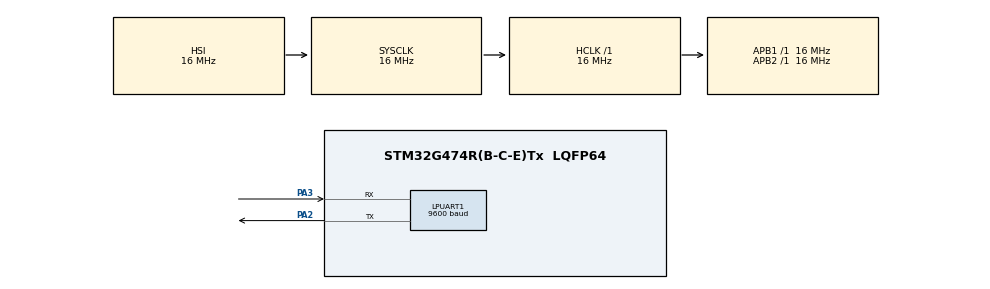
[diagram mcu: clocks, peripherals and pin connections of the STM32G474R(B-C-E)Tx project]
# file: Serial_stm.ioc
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LPUART1.BaudRate=9600
Mcu.Family=STM32G4
Mcu.Name=STM32G474R(B-C-E)Tx
Mcu.Package=LQFP64
NVIC.LPUART1_IRQn=true\:0\:0\:false\:false\:true\:true\:true
NVIC.PriorityGroup=NVIC_PRIORITYGROUP_4
PA2.Mode=Asynchronous
PA2.Signal=LPUART1_TX
PA3.Mode=Asynchronous
PA3.Signal=LPUART1_RX
ProjectManager.HeapSize=0x200
ProjectManager.StackSize=0x400
ProjectManager.TargetToolchain=STM32CubeIDE
RCC.AHBFreq_Value=16000000
RCC.APB1Freq_Value=16000000
RCC.APB1TimFreq_Value=16000000
RCC.APB2Freq_Value=16000000
RCC.APB2TimFreq_Value=16000000
RCC.CortexFreq_Value=16000000
RCC.EXTERNAL_CLOCK_VALUE=12288000
RCC.HCLKFreq_Value=16000000
RCC.HSE_VALUE=8000000
RCC.HSI48_VALUE=48000000
RCC.HSI_VALUE=16000000
RCC.LSE_VALUE=32768
RCC.SYSCLKFreq_VALUE=16000000
RCC.USBFreq_Value=64000000
RCC.VCOOutputFreq_Value=128000000
VP_SYS_VS_DBSignals.Mode=DisableDeadBatterySignals
board=custom

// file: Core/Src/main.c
/* USER CODE BEGIN Header */
/**
  ******************************************************************************
  * @file           : main.c
  * @brief          : Main program body
  ******************************************************************************
  * @attention
  *
  * <h2><center>&copy; Copyright (c) 2022 STMicroelectronics.
  * All rights reserved.</center></h2>
  *
  * This software component is licensed by ST under BSD 3-Clause license,
  * the "License"; You may not use this file except in compliance with the
  * License. You may obtain a copy of the License at:
  *                        opensource.org/licenses/BSD-3-Clause
  *
  ******************************************************************************
  */
/* USER CODE END Header */
#include "main.h"
#include "string.h"
#include <stdio.h>
#include <time.h>

UART_HandleTypeDef hlpuart1;

void SystemClock_Config(void);
static void MX_GPIO_Init(void);
static void MX_LPUART1_UART_Init(void);

/* USER CODE BEGIN 0 */
uint8_t data[17];
uint16_t CalcCRC(uint8_t *data_t, uint16_t length)
{
	unsigned int temp, temp2, flag;
	temp = 0xFFFF;
	for(int i = 0; i < length; i++)
	{
		temp = temp ^ data[i];
		for(int j = 0; j < length; j++)
		{
			flag = temp & 0x0001;
			temp >>= 1;
			if(flag)
				temp ^= 0xA001;
		}
	}
	// reverse byte order.
	temp2 = temp >> 8;
	temp = (temp << 8) | temp2;
	temp &= 0xFFFF;
	return temp;
}

//tao 1 mang random 12 phan tu
void initRandomArray(uint8_t *A, int n, uint8_t k) {
    srand(time(NULL));
    uint8_t randNum = 0;
    for (int i = 0; i < n; i++) {
        randNum = 48 + rand() % k;
        A[i] = randNum;
        printf("%d\n", A[i]);
    }
}
/* USER CODE END 0 */

int main(void)
{
  /* USER CODE BEGI5 1 */
  /* USER CODE END 1 */

  /* MCU Configuration--------------------------------------------------------*/

  /* Reset of all peripherals, Initializes the Flash interface and the Systick. */
  HAL_Init();

  /* USER CODE BEGIN Init */
  uint8_t arrayRandom[12];
  uint8_t k = 78;
  int count = 0;
  initRandomArray(arrayRandom, sizeof(arrayRandom), k);
  // truyen gia tri cho data
  data[0] = 0x42;		// byte 0, 1: header
  data[1] = 0x4C;
  data[2] = 0x0C;		// byte 2, 3: byte CMD
  for(int i = 0; i < sizeof(arrayRandom); i++)
  {
	  data[i + 3] = arrayRandom[i];
  }
  data[15] = CalcCRC(data, 15) >> 8;		// byte 15: CRC
  data[16] = CalcCRC(data, 15);
  /* USER CODE END Init */

  /* Configure the system clock */
  SystemClock_Config();

  /* Initialize all configured peripherals */
  MX_GPIO_Init();
  MX_LPUART1_UART_Init();
  /* USER CODE BEGIN 2 */
//  HAL_UART_Receive_IT(&hlpuart1, rxBuffer, 5);
  //HAL_UART_Transmit(&hlpuart1, rxBuffer, 3, 100);
  /* USER CODE END 2 */

  /* Infinite loop */
  while (1)
  {
	 // initRandomArray(arrayRandom, sizeof(arrayRandom), k);
	  HAL_UART_Transmit_IT(&hlpuart1, data, sizeof(data));
	  count++;
	  if(count > 10)
	  {
		  initRandomArray(arrayRandom, sizeof(arrayRandom), k);
		  data[0] = 0x42;		// byte 0, 1: header
		  data[1] = 0x4C;
		  data[2] = 0x0C;		// byte 2, 3: byte CMD
		  for(int i = 0; i < sizeof(arrayRandom); i++)
		  {
			  data[i + 3] = arrayRandom[i];
		  }
		  data[15] = CalcCRC(data, 15) >> 8;		// byte 15: CRC
		  data[16] = CalcCRC(data, 15);
		  count = 0;
	  }
	  HAL_Delay(1000);
  }
}

void SystemClock_Config(void)
{
  RCC_OscInitTypeDef RCC_OscInitStruct = {0};
  RCC_ClkInitTypeDef RCC_ClkInitStruct = {0};
  RCC_PeriphCLKInitTypeDef PeriphClkInit = {0};

  /** Configure the main internal regulator output voltage
  */
  HAL_PWREx_ControlVoltageScaling(PWR_REGULATOR_VOLTAGE_SCALE1);
  /** Initializes the RCC Oscillators according to the specified parameters
  * in the RCC_OscInitTypeDef structure.
  */
  RCC_OscInitStruct.OscillatorType = RCC_OSCILLATORTYPE_HSI;
  RCC_OscInitStruct.HSIState = RCC_HSI_ON;
  RCC_OscInitStruct.HSICalibrationValue = RCC_HSICALIBRATION_DEFAULT;
  RCC_OscInitStruct.PLL.PLLState = RCC_PLL_NONE;
  if (HAL_RCC_OscConfig(&RCC_OscInitStruct) != HAL_OK)
  {
    Error_Handler();
  }
  /** Initializes the CPU, AHB and APB buses clocks
  */
  RCC_ClkInitStruct.ClockType = RCC_CLOCKTYPE_HCLK|RCC_CLOCKTYPE_SYSCLK
                              |RCC_CLOCKTYPE_PCLK1|RCC_CLOCKTYPE_PCLK2;
  RCC_ClkInitStruct.SYSCLKSource = RCC_SYSCLKSOURCE_HSI;
  RCC_ClkInitStruct.AHBCLKDivider = RCC_SYSCLK_DIV1;
  RCC_ClkInitStruct.APB1CLKDivider = RCC_HCLK_DIV1;
  RCC_ClkInitStruct.APB2CLKDivider = RCC_HCLK_DIV1;

  if (HAL_RCC_ClockConfig(&RCC_ClkInitStruct, FLASH_LATENCY_0) != HAL_OK)
  {
    Error_Handler();
  }
  /** Initializes the peripherals clocks
  */
  PeriphClkInit.PeriphClockSelection = RCC_PERIPHCLK_LPUART1;
  PeriphClkInit.Lpuart1ClockSelection = RCC_LPUART1CLKSOURCE_PCLK1;
  if (HAL_RCCEx_PeriphCLKConfig(&PeriphClkInit) != HAL_OK)
  {
    Error_Handler();
  }
}

static void MX_LPUART1_UART_Init(void)
{

  hlpuart1.Instance = LPUART1;
  hlpuart1.Init.BaudRate = 9600;
  hlpuart1.Init.WordLength = UART_WORDLENGTH_8B;
  hlpuart1.Init.StopBits = UART_STOPBITS_1;
  hlpuart1.Init.Parity = UART_PARITY_NONE;
  hlpuart1.Init.Mode = UART_MODE_TX_RX;
  hlpuart1.Init.HwFlowCtl = UART_HWCONTROL_NONE;
  hlpuart1.Init.OneBitSampling = UART_ONE_BIT_SAMPLE_DISABLE;
  hlpuart1.Init.ClockPrescaler = UART_PRESCALER_DIV1;
  hlpuart1.AdvancedInit.AdvFeatureInit = UART_ADVFEATURE_NO_INIT;
  if (HAL_UART_Init(&hlpuart1) != HAL_OK)
  {
    Error_Handler();
  }
  if (HAL_UARTEx_SetTxFifoThreshold(&hlpuart1, UART_TXFIFO_THRESHOLD_1_8) != HAL_OK)
  {
    Error_Handler();
  }
  if (HAL_UARTEx_SetRxFifoThreshold(&hlpuart1, UART_RXFIFO_THRESHOLD_1_8) != HAL_OK)
  {
    Error_Handler();
  }
  if (HAL_UARTEx_DisableFifoMode(&hlpuart1) != HAL_OK)
  {
    Error_Handler();
  }

}

static void MX_GPIO_Init(void)
{

  /* GPIO Ports Clock Enable */
  __HAL_RCC_GPIOA_CLK_ENABLE();

}

/* USER CODE BEGIN 4 */
void HAL_UART_RxCpltCallback(UART_HandleTypeDef *hlpuart)
{
//	if(hlpuart->Instance == hlpuart1.Instance)
//	{
//		HAL_UART_Receive_IT(&hlpuart1, rxBuffer,5);
//		for(int i = 0; i < sizeof(rxBuffer); i++)
//		{
//			txBuffer[i] = rxBuffer[i];
//		}
//		HAL_UART_Transmit(&hlpuart1, txBuffer,5,100);
//	//	HAL_UART_Transmit(&hlpuart1, *data, strlen(data), 100);
//	//	HAL_Delay(1000);
//	}
}
/* USER CODE END 4 */

void Error_Handler(void)
{
  __disable_irq();
  while (1)
  {
  }
}

/************************ (C) COPYRIGHT STMicroelectronics *****END OF FILE****/
